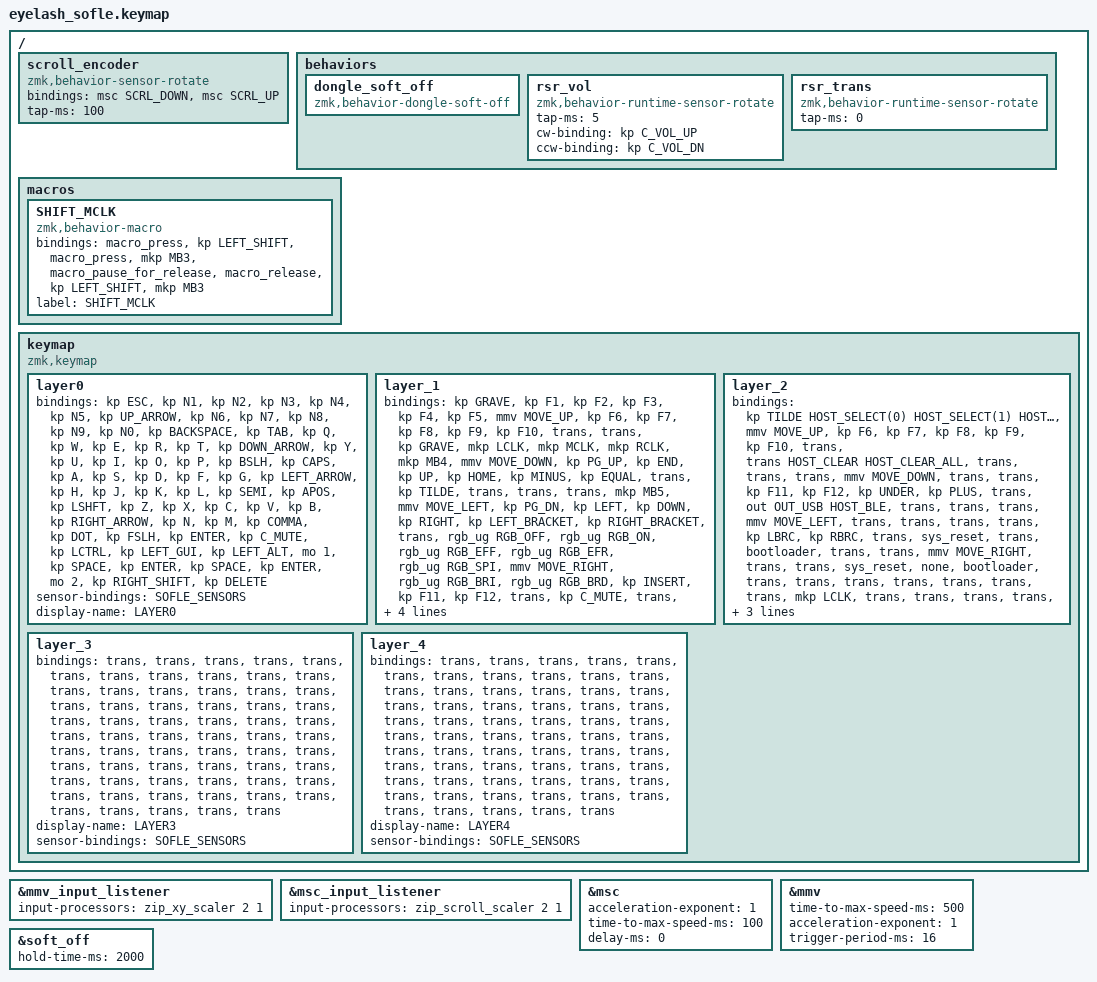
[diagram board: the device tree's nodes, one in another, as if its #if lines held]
#define ZMK_POINTING_DEFAULT_MOVE_VAL 1200  // 600
#define ZMK_POINTING_DEFAULT_SCRL_VAL 25   // 10

#include <input/processors.dtsi>
#include <zephyr/dt-bindings/input/input-event-codes.h>
#include <behaviors.dtsi>
#include <behaviors/runtime-sensor-rotate.dtsi>
#include <dt-bindings/zmk/bt.h>
#include <dt-bindings/zmk/keys.h>
#include <dt-bindings/zmk/outputs.h>
#include <dt-bindings/zmk/pointing.h>
#include <dt-bindings/zmk/rgb.h>

#ifdef SOFLE_DONGLE
#define HOST_SELECT(n) &none
#define HOST_CLEAR &none
#define HOST_CLEAR_ALL &none
#define HOST_BLE &none
#define SOFLE_SENSORS &rsr_vol
#else
#define HOST_SELECT(n) &bt BT_SEL n
#define HOST_CLEAR &bt BT_CLR
#define HOST_CLEAR_ALL &bt BT_CLR_ALL
#define HOST_BLE &out OUT_BLE
#define SOFLE_SENSORS &rsr_vol &rsr_trans
#endif

&mmv_input_listener { input-processors = <&zip_xy_scaler 2 1>; };

&msc_input_listener { input-processors = <&zip_scroll_scaler 2 1>; };

&msc {
    acceleration-exponent = <1>;      // 0
    time-to-max-speed-ms = <100>;       // 300
    delay-ms = <0>;                   // 0
};

&mmv {
    time-to-max-speed-ms = <500>;
    acceleration-exponent = <1>;
    trigger-period-ms = <16>;
};

&soft_off { hold-time-ms = <2000>; };

#include "hold_tap.dtsi"

/ {
    scroll_encoder: scroll_encoder {
        compatible = "zmk,behavior-sensor-rotate";
        #sensor-binding-cells = <0>;
        bindings = <&msc SCRL_DOWN>, <&msc SCRL_UP>;

        tap-ms = <100>;
    };

    behaviors {
#ifdef SOFLE_DONGLE
        dongle_soft_off: dongle_soft_off {
            compatible = "zmk,behavior-dongle-soft-off";
            #binding-cells = <0>;
        };
#endif
        rsr_vol: rsr_vol {
            compatible = "zmk,behavior-runtime-sensor-rotate";
            #sensor-binding-cells = <0>;
            tap-ms = <5>;
            cw-binding = <&kp C_VOL_UP>;
            ccw-binding = <&kp C_VOL_DN>;
        };

        rsr_trans: rsr_trans {
            compatible = "zmk,behavior-runtime-sensor-rotate";
            #sensor-binding-cells = <0>;
            tap-ms = <0>;
        };
    };

    macros {
        SHIFT_MCLK: SHIFT_MCLK {
            compatible = "zmk,behavior-macro";
            #binding-cells = <0>;
            bindings =
                <&macro_press>,
                <&kp LEFT_SHIFT>,
                <&macro_press>,
                <&mkp MB3>,
                <&macro_pause_for_release>,
                <&macro_release>,
                <&kp LEFT_SHIFT &mkp MB3>;

            label = "SHIFT_MCLK";
        };
    };

    keymap {
        compatible = "zmk,keymap";

        layer0 {
            bindings = <
&kp ESC     &kp N1     &kp N2        &kp N3        &kp N4  &kp N5       &kp UP_ARROW     &kp N6     &kp N7     &kp N8     &kp N9           &kp N0      &kp BACKSPACE
&kp TAB     &kp Q      &kp W         &kp E         &kp R   &kp T        &kp DOWN_ARROW   &kp Y      &kp U      &kp I      &kp O            &kp P       &kp BSLH
&kp CAPS    &kp A      &kp S         &kp D         &kp F   &kp G        &kp LEFT_ARROW   &kp H      &kp J      &kp K      &kp L            &kp SEMI    &kp APOS
&kp LSHFT   &kp Z      &kp X         &kp C         &kp V   &kp B        &kp RIGHT_ARROW  &kp N      &kp M      &kp COMMA  &kp DOT          &kp FSLH    &kp ENTER
&kp C_MUTE  &kp LCTRL  &kp LEFT_GUI  &kp LEFT_ALT  &mo 1   &kp SPACE    &kp ENTER        &kp SPACE  &kp ENTER  &mo 2      &kp RIGHT_SHIFT  &kp DELETE
            >;

            sensor-bindings = <SOFLE_SENSORS>;
            display-name = "LAYER0";
        };

        layer_1 {
            bindings = <
&kp GRAVE   &kp F1           &kp F2          &kp F3           &kp F4           &kp F5             &mmv MOVE_UP     &kp F6           &kp F7           &kp F8      &kp F9     &kp F10           &trans
&trans      &kp GRAVE        &mkp LCLK       &mkp MCLK        &mkp RCLK        &mkp MB4           &mmv MOVE_DOWN   &kp PG_UP        &kp END          &kp UP      &kp HOME   &kp MINUS         &kp EQUAL
&trans      &kp TILDE        &trans          &trans           &trans           &mkp MB5           &mmv MOVE_LEFT   &kp PG_DN        &kp LEFT         &kp DOWN    &kp RIGHT  &kp LEFT_BRACKET  &kp RIGHT_BRACKET
&trans      &rgb_ug RGB_OFF  &rgb_ug RGB_ON  &rgb_ug RGB_EFF  &rgb_ug RGB_EFR  &rgb_ug RGB_SPI    &mmv MOVE_RIGHT  &rgb_ug RGB_BRI  &rgb_ug RGB_BRD  &kp INSERT  &kp F11    &kp F12           &trans
&kp C_MUTE  &trans           &trans          &trans           &trans           &trans             &mkp LCLK        &trans           &trans           &trans      &trans     &trans
            >;

            sensor-bindings = <SOFLE_SENSORS>;
            display-name = "LAYER1";
        };

        layer_2 {
            bindings = <
&kp TILDE  HOST_SELECT(0) HOST_SELECT(1) HOST_SELECT(2) HOST_SELECT(3) HOST_SELECT(4) &mmv MOVE_UP     &kp F6  &kp F7  &kp F8      &kp F9     &kp F10      &trans
&trans     HOST_CLEAR    HOST_CLEAR_ALL  &trans        &trans        &trans          &mmv MOVE_DOWN   &trans  &trans  &kp F11     &kp F12    &kp UNDER    &kp PLUS
&trans     &out OUT_USB  HOST_BLE        &trans        &trans        &trans          &mmv MOVE_LEFT   &trans  &trans  &trans      &trans     &kp LBRC     &kp RBRC
&trans     &sys_reset    &trans          &bootloader   &trans        &trans          &mmv MOVE_RIGHT  &trans  &trans  &sys_reset  &none       &bootloader  &trans
&trans     &trans        &trans          &trans        &trans        &trans          &mkp LCLK        &trans  &trans  &trans      &trans     &trans
            >;

            display-name = "LAYER2";
            sensor-bindings = <SOFLE_SENSORS>;
        };

        layer_3 {
            bindings = <
&trans  &trans  &trans  &trans  &trans  &trans    &trans  &trans  &trans  &trans  &trans  &trans  &trans
&trans  &trans  &trans  &trans  &trans  &trans    &trans  &trans  &trans  &trans  &trans  &trans  &trans
&trans  &trans  &trans  &trans  &trans  &trans    &trans  &trans  &trans  &trans  &trans  &trans  &trans
&trans  &trans  &trans  &trans  &trans  &trans    &trans  &trans  &trans  &trans  &trans  &trans  &trans
&trans  &trans  &trans  &trans  &trans  &trans    &trans  &trans  &trans  &trans  &trans  &trans
            >;

            display-name = "LAYER3";
            sensor-bindings = <SOFLE_SENSORS>;
        };

        layer_4 {
            bindings = <
&trans  &trans  &trans  &trans  &trans  &trans    &trans  &trans  &trans  &trans  &trans  &trans  &trans
&trans  &trans  &trans  &trans  &trans  &trans    &trans  &trans  &trans  &trans  &trans  &trans  &trans
&trans  &trans  &trans  &trans  &trans  &trans    &trans  &trans  &trans  &trans  &trans  &trans  &trans
&trans  &trans  &trans  &trans  &trans  &trans    &trans  &trans  &trans  &trans  &trans  &trans  &trans
&trans  &trans  &trans  &trans  &trans  &trans    &trans  &trans  &trans  &trans  &trans  &trans
            >;

            display-name = "LAYER4";
            sensor-bindings = <SOFLE_SENSORS>;
        };
    };
};
